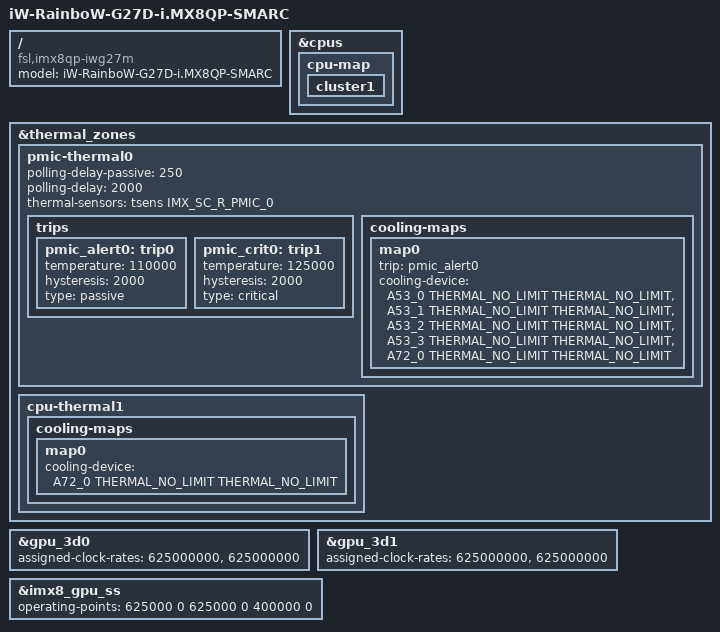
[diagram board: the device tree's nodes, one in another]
// SPDX-License-Identifier: GPL-2.0+
/*
 * Copyright (c) 2021 iWave Systems Technologies Pvt. Ltd.
 *
 * This program is free software; you can redistribute it and/or
 * modify it under the terms of the GNU General Public License
 * as published by the Free Software Foundation; either version 2
 * of the License, or (at your option) any later version.
 *
 * This program is distributed in the hope that it will be useful,
 * but WITHOUT ANY WARRANTY; without even the implied warranty of
 * MERCHANTABILITY or FITNESS FOR A PARTICULAR PURPOSE.  See the
 * GNU General Public License for more details.
 */

#include "imx8qm-iwg27d.dts"

/ {
        model = "iW-RainboW-G27D-i.MX8QP-SMARC";
        compatible = "fsl,imx8qp-iwg27m", "fsl,imx8qp", "fsl,imx8qm";
};

&cpus {
        cpu-map {
                cluster1 {
                        /delete-node/ core1;
                };
        };
        /delete-node/ cpu@101;
};

&thermal_zones { /* Thermal Sensor Zone */
        pmic-thermal0 {
                polling-delay-passive = <250>;
                polling-delay = <2000>;
                thermal-sensors = <&tsens IMX_SC_R_PMIC_0>;
                trips {
                        pmic_alert0: trip0 {
                                temperature = <110000>;
                                hysteresis = <2000>;
                                type = "passive";
                        };
                        pmic_crit0: trip1 {
                                temperature = <125000>;
                                hysteresis = <2000>;
                                type = "critical";
                        };
                };
                cooling-maps {
                        map0 {
                                trip = <&pmic_alert0>;
                                cooling-device =
                                <&A53_0 THERMAL_NO_LIMIT THERMAL_NO_LIMIT>,
                                <&A53_1 THERMAL_NO_LIMIT THERMAL_NO_LIMIT>,
                                <&A53_2 THERMAL_NO_LIMIT THERMAL_NO_LIMIT>,
                                <&A53_3 THERMAL_NO_LIMIT THERMAL_NO_LIMIT>,
                                <&A72_0 THERMAL_NO_LIMIT THERMAL_NO_LIMIT>;
                        };
                };

        };
};

&gpu_3d0 {
      assigned-clock-rates = <625000000>, <625000000>;
};

&gpu_3d1 {
      assigned-clock-rates = <625000000>, <625000000>;
};

&imx8_gpu_ss {/*<freq-kHz vol-uV>*/
        operating-points = <
        /*nominal*/     625000  0
                                625000  0
/*underdrive*/  400000  0  /*core/shader clock share the same frequency on underdrive mode*/
        >;
};

&thermal_zones {
        cpu-thermal1 {
                cooling-maps {
                        map0 {
                                cooling-device =
                                <&A72_0 THERMAL_NO_LIMIT THERMAL_NO_LIMIT>;
                        };
                };
        };
};

